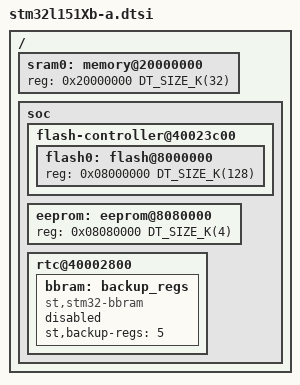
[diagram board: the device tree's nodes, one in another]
/*
 * Copyright (c) 2019 Linaro Limited
 *
 * SPDX-License-Identifier: Apache-2.0
 */

#include <mem.h>
#include <st/l1/stm32l151.dtsi>

/ {
	sram0: memory@20000000 {
		reg = <0x20000000 DT_SIZE_K(32)>;
	};

	soc {
		flash-controller@40023c00 {
			flash0: flash@8000000 {
				reg = <0x08000000 DT_SIZE_K(128)>;
			};
		};

		eeprom: eeprom@8080000 {
			reg = <0x08080000 DT_SIZE_K(4)>;
		};

		rtc@40002800 {
			bbram: backup_regs {
				compatible = "st,stm32-bbram";
				st,backup-regs = <5>;
				status = "disabled";
			};
		};
	};
};
